# AVR16EB32 register map
Vendor: Atmel; File version: 1.0
CPU: other r0p0, little endian, no MPU, no FPU, 4 interrupt priority bits
Registers are 8-bit, read-write, reset 0x0 unless marked. A register's access mark holds for its fields unless they carry their own. Offsets are from the block's base; [hi:lo] are bit positions; {n}, {i} and the like mark numbered series; 'fields as' and 'values as' point back to an identical list.

## PORTA — I/O Ports
Base 0x00800400
Same registers: PORTD 0x00800460, PORTF 0x008004A0
0x00 DIR — Data Direction
0x01 DIRSET — Data Direction Set
0x02 DIRCLR — Data Direction Clear
0x03 DIRTGL — Data Direction Toggle
0x04 OUT — Output Value
0x05 OUTSET — Output Value Set
0x06 OUTCLR — Output Value Clear
0x07 OUTTGL — Output Value Toggle
0x08 IN — Input Value
0x09 INTFLAGS — Interrupt Flags
  [7:0] INT — Pin Interrupt Flag
0x0A PORTCTRL — Port Control
  [0] SRL — Slew Rate Limit Enable
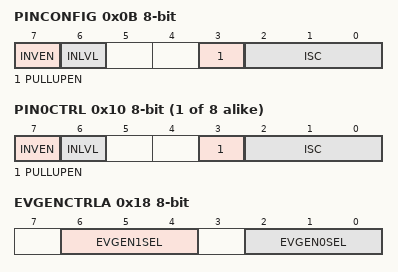
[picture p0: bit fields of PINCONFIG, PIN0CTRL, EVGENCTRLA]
0x0B PINCONFIG — Pin Control Config
  [7] INVEN — Inverted I/O Enable
  [6] INLVL — Input Level Select
    0=ST (Schmitt-Trigger input level); 1=TTL (TTL Input level)
  [3] PULLUPEN — Pullup enable
  [2:0] ISC — Input/Sense Configuration
    0=INTDISABLE (Interrupt disabled but input buffer enabled); 1=BOTHEDGES (Sense Both Edges); 2=RISING (Sense Rising Edge); 3=FALLING (Sense Falling Edge); 4=INPUT_DISABLE (Digital Input Buffer disabled); 5=LEVEL (Sense low Level)
0x0C PINCTRLUPD — Pin Control Update
0x0D PINCTRLSET — Pin Control Set
0x0E PINCTRLCLR — Pin Control Clear
{0x10+i} PIN{i}CTRL (i=0..7) — Pin {i} Control
  fields as PINCONFIG
0x18 EVGENCTRLA — Event Generation Control A
  [6:4] EVGEN1SEL — Event Generator 1 Select
    {v}=PIN{v} (Pin {v} used as event generator) (v=0..7)
  [2:0] EVGEN0SEL — Event Generator 0 Select
    {v}=PIN{v} (Pin {v} used as event generator) (v=0..7)

## PORTC — I/O Ports
Base 0x00800440
Registers as PORTA, without PORTCTRL; these are added or differ:
0x0A PORTCTRL — Port Control
  [0] SRL — Slew Rate Limit Enable

## PORTMUX — Port Multiplexer
Base 0x008005E0
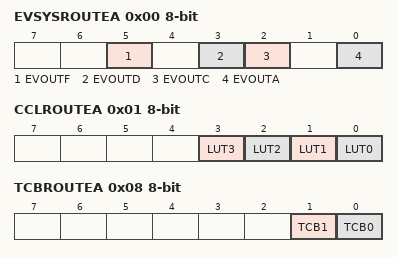
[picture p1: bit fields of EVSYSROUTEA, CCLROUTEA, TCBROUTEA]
0x00 EVSYSROUTEA
  [5] EVOUTF — Event Output F
    0=DEFAULT (EVOUTF: PF2); 1=ALT1 (EVOUTF: PF7)
  [3] EVOUTD — Event Output D
    0=DEFAULT (EVOUTD: PD2); 1=ALT1 (EVOUTD: PD7)
  [2] EVOUTC — Event Output C
    0=DEFAULT (EVOUTC: PC2)
  [0] EVOUTA — Event Output A
    0=DEFAULT (EVOUTA: PA2); 1=ALT1 (EVOUTA: PA7)
0x01 CCLROUTEA
  [3] LUT3 — CCL Look-Up Table 3 Signals
    0=DEFAULT (Out: PF3 In: PF0, PF1, PF2)
  [2] LUT2 — CCL Look-Up Table 2 Signals
    0=DEFAULT (Out: PD3 In: PD0, PD1, PD2); 1=ALT1 (Out: PD6 In: PD0, PD1, PD2)
  [1] LUT1 — CCL Look-Up Table 1 Signals
    0=DEFAULT (Out: PC3 In: PC0, PC1, PC2); 1=ALT1 (Out: - In: PC0, PC1, PC2)
  [0] LUT0 — CCL Look-Up Table 0 Signals
    0=DEFAULT (Out: PA3 In: PA0, PA1, PA2); 1=ALT1 (Out: PA6 In: PA0, PA1, PA2)
0x02 USARTROUTEA
  [2:0] USART0 — USART0 Routing
    0=DEFAULT (TxD: PA0, RxD: PA1, XCK: PA2, XDIR: PA3); 1=ALT1 (TxD: PA4, RxD: PA5, XCK: PA6, XDIR: PA7); 2=ALT2 (TxD: PA2, RxD: PA3, XCK: -, XDIR: -); 3=ALT3 (TxD: PD4, RxD: PD5, XCK: PD6, XDIR: PD7); 4=ALT4 (TxD: PC1, RxD: PC2, XCK: PC3, XDIR: -); 6=ALT6 (TxD: PF7, RxD: PF6, XCK: -, XDIR: -); 7=NONE (Not connected to any pins)
0x05 SPIROUTEA
  [2:0] SPI0 — SPI0 Signals
    0=DEFAULT (MOSI: PA4, MISO: PA5, SCK: PA6, SS: PA7); 3=ALT3 (MOSI: PA0, MISO: PA1, SCK: PC0, SS: PC1); 4=ALT4 (MOSI: PD4, MISO: PD5, SCK: PD6, SS: PD7); 5=ALT5 (MOSI: PC0, MISO: PC1, SCK: PC2, SS: PC3); 6=ALT6 (MOSI: PC1, MISO: PC2, SCK: PC3, SS: PF7); 7=NONE (Not connected to any pins, SS set to 1)
0x06 TWIROUTEA
  [1:0] TWI0 — TWI0 Signals
    0=DEFAULT (SDA: PA2, SCL: PA3. Dual mode: SDA: PC2, SCL: PC3); 1=ALT1 (SDA: PA2, SCL: PA3. Dual mode: SDA: -, SCL: -); 2=ALT2 (SDA: PC2, SCL: PC3. Dual mode: SDA: -, SCL: -); 3=ALT3 (SDA: PA0, SCL: PA1. Dual mode: SDA: PC2, SCL: PC3)
0x07 TCEROUTEA
  [3:0] TCE0 — TCE0 Signals
    0=PORTA (WOn: PA0, PA1, PA2, PA3, PA4, PA5, PA6, PA7); 2=PORTC (WOn: PC0, PC1, PC2, PC3, -, -, -, -); 3=PORTD (WOn: PD0, PD1, PD2, PD3, PD4, PD5, PD6, PD7); 5=PORTF (WOn: PF0, PF1, PF2, PF3, PF4, PF5, -, -); 8=PORTC2 (WOn: PA0, PA1, PC0, PC1, PC2, PC3, -, -); 9=PORTA2 (WOn: PA2, PA3, PA4, PA5, PA6, PA7, -, -)
0x08 TCBROUTEA
  [1] TCB1 — TCB1 Output
    0=DEFAULT (WO: PA3); 1=ALT1 (WO: PF5)
  [0] TCB0 — TCB0 Output
    0=DEFAULT (WO: PA2); 1=ALT1 (WO: PF4)
0x0C TCFROUTEA
  [1:0] TCF0 — TCF0 Output
    0=DEFAULT (WOn: PA0, PA1); 1=ALT1 (WOn: PA6, PA7); 2=ALT2 (WOn: PF4, PF5)
